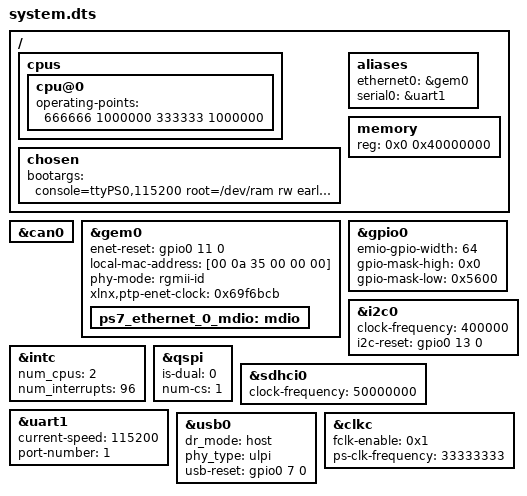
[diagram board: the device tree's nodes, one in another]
/*
 * CAUTION: This file is automatically generated by Xilinx.
 * Version:  
 * Today is: Wed Feb  4 23:00:29 2015
*/


/dts-v1/;
/include/ "zynq-7000.dtsi"
/include/ "pl.dtsi"
/ {
	cpus {
		cpu@0 {
			operating-points = <666666 1000000 333333 1000000>;
		};
	};
	chosen {
		bootargs = "console=ttyPS0,115200 root=/dev/ram rw earlyprintk";
	};
	aliases {
		ethernet0 = &gem0;
		serial0 = &uart1;
	};
	memory {
		device_type = "memory";
		reg = <0x0 0x40000000>;
	};
};
&can0 {
	status = "okay";
};
&gem0 {
	enet-reset = <&gpio0 11 0>;
	local-mac-address = [00 0a 35 00 00 00];
	phy-mode = "rgmii-id";
	status = "okay";
	xlnx,ptp-enet-clock = <0x69f6bcb>;
	ps7_ethernet_0_mdio: mdio {
		#address-cells = <1>;
		#size-cells = <0>;
	};
};
&gpio0 {
	emio-gpio-width = <64>;
	gpio-mask-high = <0x0>;
	gpio-mask-low = <0x5600>;
};
&i2c0 {
	clock-frequency = <400000>;
	i2c-reset = <&gpio0 13 0>;
	status = "okay";
};
&intc {
	num_cpus = <2>;
	num_interrupts = <96>;
};
&qspi {
	is-dual = <0>;
	num-cs = <1>;
	status = "okay";
};
&sdhci0 {
	clock-frequency = <50000000>;
	status = "okay";
};
&uart1 {
	current-speed = <115200>;
	device_type = "serial";
	port-number = <1>;
	status = "okay";
};
&usb0 {
	dr_mode = "host";
	phy_type = "ulpi";
	status = "okay";
	usb-reset = <&gpio0 7 0>;
};
&clkc {
	fclk-enable = <0x1>;
	ps-clk-frequency = <33333333>;
};
